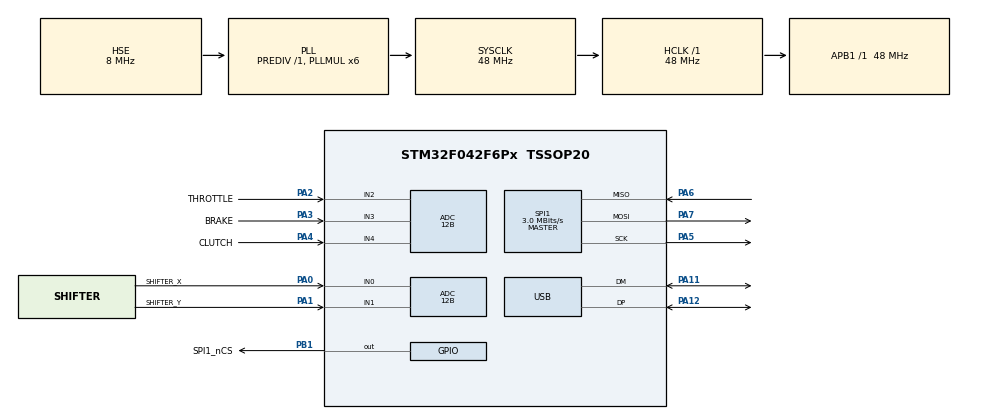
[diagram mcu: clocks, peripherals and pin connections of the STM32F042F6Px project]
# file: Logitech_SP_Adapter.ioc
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ADC.ClockPrescaler=ADC_CLOCK_ASYNC_DIV1
ADC.ContinuousConvMode=ENABLE
ADC.DMAContinuousRequests=ENABLE
ADC.DataAlign=ADC_DATAALIGN_RIGHT
ADC.DiscontinuousConvMode=DISABLE
ADC.EOCSelection=ADC_EOC_SEQ_CONV
ADC.EnableAnalogWatchDog=false
ADC.ExternalTrigConvEdge=ADC_EXTERNALTRIGCONVEDGE_NONE
ADC.LowPowerAutoPowerOff=DISABLE
ADC.LowPowerAutoWait=DISABLE
ADC.Overrun=ADC_OVR_DATA_OVERWRITTEN
ADC.Resolution=ADC_RESOLUTION_12B
ADC.SamplingTime=ADC_SAMPLETIME_7CYCLES_5
ADC.ScanConvMode=ADC_SCAN_DIRECTION_FORWARD
Dma.ADC.0.Direction=DMA_PERIPH_TO_MEMORY
Dma.ADC.0.Instance=DMA1_Channel1
Dma.ADC.0.MemDataAlignment=DMA_MDATAALIGN_WORD
Dma.ADC.0.MemInc=DMA_MINC_ENABLE
Dma.ADC.0.Mode=DMA_CIRCULAR
Dma.ADC.0.PeriphDataAlignment=DMA_PDATAALIGN_WORD
Dma.ADC.0.PeriphInc=DMA_PINC_DISABLE
Dma.ADC.0.Priority=DMA_PRIORITY_HIGH
Dma.Request0=ADC
Mcu.Family=STM32F0
Mcu.Name=STM32F042F6Px
Mcu.Package=TSSOP20
NVIC.DMA1_Channel1_IRQn=true\:0\:0\:false\:false\:true
NVIC.TIM14_IRQn=true\:0\:0\:false\:false\:true
NVIC.USB_IRQn=true\:0\:0\:false\:false\:true
PA0.GPIO_Label=SHIFTER_X
PA0.Mode=IN0
PA0.Signal=ADC_IN0
PA1.GPIO_Label=SHIFTER_Y
PA1.Mode=IN1
PA1.Signal=ADC_IN1
PA11.Mode=Device
PA11.Signal=USB_DM
PA12.Mode=Device
PA12.Signal=USB_DP
PA13.Mode=Serial_Wire
PA13.Signal=SYS_SWDIO
PA14.Mode=Serial_Wire
PA14.Signal=SYS_SWCLK
PA2.GPIO_Label=THROTTLE
PA2.Mode=IN2
PA2.Signal=ADC_IN2
PA3.GPIO_Label=BRAKE
PA3.Mode=IN3
PA3.Signal=ADC_IN3
PA4.GPIO_Label=CLUTCH
PA4.Mode=IN4
PA4.Signal=ADC_IN4
PA5.Mode=Full_Duplex_Master
PA5.Signal=SPI1_SCK
PA6.Mode=Full_Duplex_Master
PA6.Signal=SPI1_MISO
PA7.Mode=Full_Duplex_Master
PA7.Signal=SPI1_MOSI
PB1.GPIO_Label=SPI1_nCS
PB1.GPIO_Speed=GPIO_SPEED_FREQ_HIGH
PB1.Signal=GPIO_Output
PF0-OSC_IN.Mode=HSE-External-Oscillator
PF0-OSC_IN.Signal=RCC_OSC_IN
PF1-OSC_OUT.Mode=HSE-External-Oscillator
PF1-OSC_OUT.Signal=RCC_OSC_OUT
ProjectManager.HeapSize=0x200
ProjectManager.StackSize=0x400
ProjectManager.TargetToolchain=TrueSTUDIO
RCC.AHBFreq_Value=48000000
RCC.APB1Freq_Value=48000000
RCC.APB1TimFreq_Value=48000000
RCC.HCLKFreq_Value=48000000
RCC.HSIState=RCC_HSI_ON
RCC.PLLMUL=RCC_PLL_MUL6
RCC.SYSCLKFreq_VALUE=48000000
RCC.SYSCLKSource=RCC_SYSCLKSOURCE_PLLCLK
RCC.USBClockSelection=RCC_USBCLKSOURCE_PLL
RCC.USBFreq_Value=48000000
SPI1.BaudRatePrescaler=SPI_BAUDRATEPRESCALER_16
SPI1.CalculateBaudRate=3.0 MBits/s
SPI1.DataSize=SPI_DATASIZE_8BIT
SPI1.Mode=SPI_MODE_MASTER
TIM14.Period=10
TIM14.Prescaler=48
USB_DEVICE.MANUFACTURER_STRING=InterBiometrics
USB_DEVICE.PID_HID_FS=61453
USB_DEVICE.PRODUCT_STRING_HID_FS=Shifter/Pedals Adapter
USB_DEVICE.USBD_HandleTypeDef=hUsbDeviceFS
USB_DEVICE.VID=4617
USB_DEVICE.VirtualMode=Hid
USB_DEVICE.VirtualModeFS=Hid_FS
VP_SYS_VS_PINREMAP.Mode=PINREMAP
VP_TIM14_VS_ClockSourceINT.Mode=Enable_Timer
VP_USB_DEVICE_VS_USB_DEVICE_HID_FS.Mode=HID_FS
board=Logitech_SP_Adapter

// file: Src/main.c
/**
  ******************************************************************************
  * File Name          : main.c
  * Description        : Main program body
  ******************************************************************************
  *
  * COPYRIGHT(c) 2016 STMicroelectronics
  *
  * Redistribution and use in source and binary forms, with or without modification,
  * are permitted provided that the following conditions are met:
  *   1. Redistributions of source code must retain the above copyright notice,
  *      this list of conditions and the following disclaimer.
  *   2. Redistributions in binary form must reproduce the above copyright notice,
  *      this list of conditions and the following disclaimer in the documentation
  *      and/or other materials provided with the distribution.
  *   3. Neither the name of STMicroelectronics nor the names of its contributors
  *      may be used to endorse or promote products derived from this software
  *      without specific prior written permission.
  *
  * THIS SOFTWARE IS PROVIDED BY THE COPYRIGHT HOLDERS AND CONTRIBUTORS "AS IS"
  * AND ANY EXPRESS OR IMPLIED WARRANTIES, INCLUDING, BUT NOT LIMITED TO, THE
  * IMPLIED WARRANTIES OF MERCHANTABILITY AND FITNESS FOR A PARTICULAR PURPOSE ARE
  * DISCLAIMED. IN NO EVENT SHALL THE COPYRIGHT HOLDER OR CONTRIBUTORS BE LIABLE
  * FOR ANY DIRECT, INDIRECT, INCIDENTAL, SPECIAL, EXEMPLARY, OR CONSEQUENTIAL
  * DAMAGES (INCLUDING, BUT NOT LIMITED TO, PROCUREMENT OF SUBSTITUTE GOODS OR
  * SERVICES; LOSS OF USE, DATA, OR PROFITS; OR BUSINESS INTERRUPTION) HOWEVER
  * CAUSED AND ON ANY THEORY OF LIABILITY, WHETHER IN CONTRACT, STRICT LIABILITY,
  * OR TORT (INCLUDING NEGLIGENCE OR OTHERWISE) ARISING IN ANY WAY OUT OF THE USE
  * OF THIS SOFTWARE, EVEN IF ADVISED OF THE POSSIBILITY OF SUCH DAMAGE.
  *
  ******************************************************************************
  */
#include "stm32f0xx_hal.h"
#include "usb_device.h"

/* USER CODE BEGIN Includes */
#include "usbd_hid.h"
#include "eeprom.h"
/* USER CODE END Includes */

TIM_HandleTypeDef htim14;

ADC_HandleTypeDef hadc;
DMA_HandleTypeDef hdma_adc;
SPI_HandleTypeDef hspi1;

#define X_AXIS_LOW_TH	1400
#define X_AXIS_HIGH_TH	2500
#define Y_AXIS_LOW_TH	500
#define Y_AXIS_HIGH_TH	2600

#define X_AXIS			(axis[0] & 0xffffu)
#define Y_AXIS			(axis[1] & 0xffffu)
#define T_AXIS			(axis[2] & 0xffffu)
#define B_AXIS			(axis[3] & 0xffffu)
#define C_AXIS			(axis[4] & 0xffffu)

__ALIGN_BEGIN static volatile uint32_t axis[5] __ALIGN_END = { 0, 0, 0, 0, 0 };    // Y, X, T, B, C
__ALIGN_BEGIN static uint8_t rx_buffer[2] __ALIGN_END;

/* Virtual address defined by the user: 0xFFFF value is prohibited */
#define X_AXIS_LOW_VADDR	0x1001
#define X_AXIS_HIGH_VADDR	0x1002
#define Y_AXIS_LOW_VADDR	0x1003
#define Y_AXIS_HIGH_VADDR	0x1004

__ALIGN_BEGIN uint16_t VirtAddVarTab[NB_OF_VAR] __ALIGN_END =
{
    X_AXIS_LOW_VADDR, X_AXIS_HIGH_VADDR, Y_AXIS_LOW_VADDR, Y_AXIS_HIGH_VADDR
};

struct __packed
{
    uint8_t		id;			// 0x01
    uint8_t		buttons[3];
    uint16_t	axis[5];
} report = { 1, { 0, 0, 0 }, { 0, 0, 0, 0, 0 } };

unsigned short x_low_th  = X_AXIS_LOW_TH;
unsigned short y_low_th  = Y_AXIS_LOW_TH;
unsigned short x_high_th = X_AXIS_HIGH_TH;
unsigned short y_high_th = Y_AXIS_HIGH_TH;

unsigned short report2send = 0;
static unsigned short x_axis = 2048;
static unsigned short y_axis = 2048;

static volatile uint32_t u100ticks = 0;

void SystemClock_Config(void);
void Error_Handler(void);
static void MX_GPIO_Init(void);
static void MX_DMA_Init(void);
static void MX_ADC_Init(void);
static void MX_SPI1_Init(void);
static void MX_TIM14_Init(void);

void HAL_ADC_ConvCpltCallback(ADC_HandleTypeDef * hadc);

int main(void)
{
    /* Reset of all peripherals, Initializes the Flash interface and the Systick. */
    HAL_Init();

    /* Configure the system clock */
    SystemClock_Config();

    /* Initialize all configured peripherals */
    MX_GPIO_Init();
    MX_DMA_Init();
    MX_ADC_Init();
    MX_SPI1_Init();
    MX_USB_DEVICE_Init();
    MX_TIM14_Init();

    HAL_FLASH_Unlock();
    EE_Init();

    EE_ReadVariable(VirtAddVarTab[0], &x_low_th);
    EE_ReadVariable(VirtAddVarTab[1], &x_high_th);
    EE_ReadVariable(VirtAddVarTab[2], &y_low_th);
    EE_ReadVariable(VirtAddVarTab[3], &y_high_th);

    HAL_FLASH_Lock();

    HAL_ADC_Start_DMA(&hadc, (uint32_t*)axis, 5);

    while (1)
    {
        HAL_GPIO_WritePin(SPI1_nCS_GPIO_Port, SPI1_nCS_Pin, GPIO_PIN_SET);

        HAL_TIM_Base_Start_IT(&htim14);
        while (!u100ticks) /* do nothing for 100 us */;
        HAL_TIM_Base_Stop_IT(&htim14);
        u100ticks = 0;

        HAL_StatusTypeDef status =
            HAL_SPI_Receive(&hspi1, rx_buffer, sizeof(rx_buffer), 3000);

        switch(status)
        {
        case HAL_OK:
            report.buttons[0] = 0x00;
            // report.buttons[1] = 0x00;
            report.buttons[2] = 0x00;

            if ((rx_buffer[0] & 0xff) != 0xff)   // if all bits of rx_buffer[0] is 1 assume shifter is disconnected
            {
                if (rx_buffer[0] & 4)   report.buttons[0] |= 1;         else report.buttons[0] &= ~1;
                if (rx_buffer[0] & 1)   report.buttons[0] |= (1 << 1);  else report.buttons[0] &= ~(1 << 1);
                if (rx_buffer[0] & 2)   report.buttons[0] |= (1 << 2);  else report.buttons[0] &= ~(1 << 2);
                if (rx_buffer[0] & 8)   report.buttons[0] |= (1 << 3);  else report.buttons[0] &= ~(1 << 3);

                if (rx_buffer[1] & 1)   report.buttons[2] |= 1;         else report.buttons[2] &= ~1;
                if (rx_buffer[1] & 2)   report.buttons[2] |= (1 << 1);  else report.buttons[2] &= ~(1 << 1);
                if (rx_buffer[1] & 4)   report.buttons[2] |= (1 << 2);  else report.buttons[2] &= ~(1 << 2);
                if (rx_buffer[1] & 8)   report.buttons[2] |= (1 << 3);  else report.buttons[2] &= ~(1 << 3);

                if (rx_buffer[1] & 32)  report.buttons[0] |= (1 << 4);  else report.buttons[0] &= ~(1 << 4);
                if (rx_buffer[1] & 128) report.buttons[0] |= (1 << 5);  else report.buttons[0] &= ~(1 << 5);
                if (rx_buffer[1] & 64)  report.buttons[0] |= (1 << 6);  else report.buttons[0] &= ~(1 << 6);
                if (rx_buffer[1] & 16)  report.buttons[0] |= (1 << 7);  else report.buttons[0] &= ~(1 << 7);
            }
            break;

        case HAL_TIMEOUT:
        case HAL_BUSY:
        case HAL_ERROR:
            Error_Handler();
        default:
            report.buttons[0] = 0xff;
            break;
        }

        HAL_GPIO_WritePin(SPI1_nCS_GPIO_Port, SPI1_nCS_Pin, GPIO_PIN_RESET);
        report.id = 0x01;

        x_axis = ((X_AXIS << 2) + x_axis * 96) / 100;
        y_axis = ((Y_AXIS << 2) + y_axis * 96) / 100;

        if (rx_buffer[0] & 16)
        {
            if (y_axis < y_low_th)   // stick towards player
            {
                report.buttons[1] = 128;
                report.buttons[2] &= ~(1 << 4);
            }
            else if (y_axis > y_high_th)   // stick opposite to player
            {
                report.buttons[1] = 0; // neutral
                report.buttons[2] |= (1 << 4);
            }
            else
            {
                report.buttons[1] = 0; // neutral
                report.buttons[2] &= ~(1 << 4);
            }
        }
        else
        {
            report.buttons[1] &= ~(1 << 7);
            report.buttons[2] &= ~(1 << 4);

            if (y_axis < y_low_th)   // stick towards player
            {
                if (x_axis < x_low_th)
                {
                    if (!report.buttons[1]) report.buttons[1] = 2; // 2nd gear
                }
                else if (!report.buttons[1])
                {
                    report.buttons[1] = (x_axis > x_high_th) ? ((rx_buffer[0] & 64) ? 64 : 32) : 8;
                }
            }
            else
            {
                if (y_axis > y_high_th)   // stick opposite to player
                {
                    if (x_axis < x_low_th)
                    {
                        if (!report.buttons[1]) report.buttons[1] = 1; // 1st gear
                    }
                    else if (!report.buttons[1])
                    {
                        report.buttons[1] = (x_axis > x_high_th) ? 16 : 4;
                    }
                }
                else
                {
                    report.buttons[1] = 0; // neutral
                }
            }
        }

        report.axis[0] = x_axis;
        report.axis[1] = y_axis;

        if (report2send == 2)
        {
            HAL_FLASH_Unlock();

            EE_WriteVariable(VirtAddVarTab[0], x_low_th);
            EE_WriteVariable(VirtAddVarTab[1], x_high_th);
            EE_WriteVariable(VirtAddVarTab[2], y_low_th);
            EE_WriteVariable(VirtAddVarTab[3], y_high_th);

            HAL_FLASH_Lock();
            report2send = 0;
        }

        if (hUsbDeviceFS.pClassData
                && ((USBD_HID_HandleTypeDef *)hUsbDeviceFS.pClassData)->state == HID_IDLE)
        {
            USBD_HID_SendReport(&hUsbDeviceFS, (uint8_t *)&report, sizeof(report));
        }
    }
}

/** System Clock Configuration
*/
void SystemClock_Config(void)
{

    RCC_OscInitTypeDef RCC_OscInitStruct;
    RCC_ClkInitTypeDef RCC_ClkInitStruct;
    RCC_PeriphCLKInitTypeDef PeriphClkInit;

    RCC_OscInitStruct.OscillatorType = RCC_OSCILLATORTYPE_HSI14|RCC_OSCILLATORTYPE_HSE;
    RCC_OscInitStruct.HSEState = RCC_HSE_ON;
//  RCC_OscInitStruct.OscillatorType = RCC_OSCILLATORTYPE_HSI14|RCC_OSCILLATORTYPE_HSI48;
//  RCC_OscInitStruct.HSI48State = RCC_HSI48_ON;

    RCC_OscInitStruct.HSI14State = RCC_HSI14_ON;
    RCC_OscInitStruct.HSI14CalibrationValue = RCC_HSI14CALIBRATION_DEFAULT;

    RCC_OscInitStruct.PLL.PLLState = RCC_PLL_ON;
//  RCC_OscInitStruct.PLL.PLLState = RCC_PLL_NONE;
    RCC_OscInitStruct.PLL.PLLSource = RCC_PLLSOURCE_HSE;
    RCC_OscInitStruct.PLL.PLLMUL = RCC_PLL_MUL6;
    RCC_OscInitStruct.PLL.PREDIV = RCC_PREDIV_DIV1;

    if (HAL_RCC_OscConfig(&RCC_OscInitStruct) != HAL_OK)
    {
        Error_Handler();
    }

    RCC_ClkInitStruct.ClockType = RCC_CLOCKTYPE_HCLK|RCC_CLOCKTYPE_SYSCLK
                                  |RCC_CLOCKTYPE_PCLK1;
    RCC_ClkInitStruct.SYSCLKSource = RCC_SYSCLKSOURCE_PLLCLK;
//  RCC_ClkInitStruct.SYSCLKSource = RCC_SYSCLKSOURCE_HSI48;

    RCC_ClkInitStruct.AHBCLKDivider = RCC_SYSCLK_DIV1;
    RCC_ClkInitStruct.APB1CLKDivider = RCC_HCLK_DIV1;
    if (HAL_RCC_ClockConfig(&RCC_ClkInitStruct, FLASH_LATENCY_1) != HAL_OK)
    {
        Error_Handler();
    }

    PeriphClkInit.PeriphClockSelection = RCC_PERIPHCLK_USB;
    PeriphClkInit.UsbClockSelection = RCC_USBCLKSOURCE_PLL;
//  PeriphClkInit.UsbClockSelection = RCC_USBCLKSOURCE_HSI48;

    if (HAL_RCCEx_PeriphCLKConfig(&PeriphClkInit) != HAL_OK)
    {
        Error_Handler();
    }

    HAL_SYSTICK_Config(HAL_RCC_GetHCLKFreq()/1000);

    HAL_SYSTICK_CLKSourceConfig(SYSTICK_CLKSOURCE_HCLK);

    /* SysTick_IRQn interrupt configuration */
    HAL_NVIC_SetPriority(SysTick_IRQn, 0, 0);
}

/* TIM14 init function */
static void MX_TIM14_Init(void)
{

    htim14.Instance = TIM14;
    htim14.Init.Prescaler = 48;
    htim14.Init.CounterMode = TIM_COUNTERMODE_UP;
    htim14.Init.Period = 100; /* generate IRQ 48 MHz / 48 / 100 = 10,000 times per second */
    htim14.Init.ClockDivision = TIM_CLOCKDIVISION_DIV1;
    if (HAL_TIM_Base_Init(&htim14) != HAL_OK)
    {
        Error_Handler();
    }

}

/* ADC init function */
static void MX_ADC_Init(void)
{

    ADC_ChannelConfTypeDef sConfig;

    /**Configure the global features of the ADC (Clock, Resolution, Data Alignment and number of conversion)
    */
    hadc.Instance = ADC1;
    hadc.Init.ClockPrescaler = ADC_CLOCK_ASYNC_DIV1;
    hadc.Init.Resolution = ADC_RESOLUTION_12B;
    hadc.Init.DataAlign = ADC_DATAALIGN_RIGHT;
    hadc.Init.ScanConvMode = ADC_SCAN_DIRECTION_FORWARD;
    hadc.Init.EOCSelection = ADC_EOC_SEQ_CONV;
    hadc.Init.LowPowerAutoWait = DISABLE;
    hadc.Init.LowPowerAutoPowerOff = DISABLE;
    hadc.Init.ContinuousConvMode = ENABLE;
    hadc.Init.DiscontinuousConvMode = DISABLE;
    hadc.Init.ExternalTrigConv = ADC_SOFTWARE_START;
    hadc.Init.SamplingTimeCommon = ADC_SAMPLETIME_239CYCLES_5;
    hadc.Init.ExternalTrigConvEdge = ADC_EXTERNALTRIGCONVEDGE_NONE;
    hadc.Init.DMAContinuousRequests = ENABLE;
    hadc.Init.Overrun = ADC_OVR_DATA_OVERWRITTEN;
    if (HAL_ADC_Init(&hadc) != HAL_OK)
    {
        Error_Handler();
    }

    /**Configure for the selected ADC regular channel to be converted.
    */
    sConfig.Channel = ADC_CHANNEL_0;
    sConfig.Rank = ADC_RANK_CHANNEL_NUMBER;
    sConfig.SamplingTime = ADC_SAMPLETIME_239CYCLES_5;
    if (HAL_ADC_ConfigChannel(&hadc, &sConfig) != HAL_OK)
    {
        Error_Handler();
    }

    /**Configure for the selected ADC regular channel to be converted.
    */
    sConfig.Channel = ADC_CHANNEL_1;
    if (HAL_ADC_ConfigChannel(&hadc, &sConfig) != HAL_OK)
    {
        Error_Handler();
    }

    /**Configure for the selected ADC regular channel to be converted.
    */
    sConfig.Channel = ADC_CHANNEL_2;
    if (HAL_ADC_ConfigChannel(&hadc, &sConfig) != HAL_OK)
    {
        Error_Handler();
    }

    /**Configure for the selected ADC regular channel to be converted.
    */
    sConfig.Channel = ADC_CHANNEL_3;
    if (HAL_ADC_ConfigChannel(&hadc, &sConfig) != HAL_OK)
    {
        Error_Handler();
    }

    /**Configure for the selected ADC regular channel to be converted.
    */
    sConfig.Channel = ADC_CHANNEL_4;
    if (HAL_ADC_ConfigChannel(&hadc, &sConfig) != HAL_OK)
    {
        Error_Handler();
    }

}

// ADC DMA interrupt handler
void HAL_ADC_ConvCpltCallback(ADC_HandleTypeDef *hadc)
{

    report.axis[2] = ((T_AXIS << 1) + report.axis[2] * 98) / 100;
    report.axis[3] = ((B_AXIS << 1) + report.axis[3] * 98) / 100;
    report.axis[4] = ((C_AXIS << 1) + report.axis[4] * 98) / 100;
}

void HAL_TIM_PeriodElapsedCallback(TIM_HandleTypeDef *htim)
{
    if (htim->Instance == TIM14)
    {
        u100ticks++;
    }
}

/* SPI1 init function */
static void MX_SPI1_Init(void)
{

    hspi1.Instance = SPI1;
    hspi1.Init.Mode = SPI_MODE_MASTER;
    hspi1.Init.Direction = SPI_DIRECTION_2LINES;
    hspi1.Init.DataSize = SPI_DATASIZE_8BIT;
    hspi1.Init.CLKPolarity = SPI_POLARITY_LOW;
    hspi1.Init.CLKPhase = SPI_PHASE_1EDGE;
    hspi1.Init.NSS = SPI_NSS_SOFT;
    hspi1.Init.BaudRatePrescaler = SPI_BAUDRATEPRESCALER_16;
    hspi1.Init.FirstBit = SPI_FIRSTBIT_MSB;
    hspi1.Init.TIMode = SPI_TIMODE_DISABLE;
    hspi1.Init.CRCCalculation = SPI_CRCCALCULATION_DISABLE;
    hspi1.Init.CRCPolynomial = 7;
    hspi1.Init.CRCLength = SPI_CRC_LENGTH_DATASIZE;
    hspi1.Init.NSSPMode = SPI_NSS_PULSE_ENABLE;
    if (HAL_SPI_Init(&hspi1) != HAL_OK)
    {
        Error_Handler();
    }

}

static void MX_DMA_Init(void)
{
    /* DMA controller clock enable */
    __HAL_RCC_DMA1_CLK_ENABLE();

    /* DMA interrupt init */
    /* DMA1_Channel1_IRQn interrupt configuration */
    HAL_NVIC_SetPriority(DMA1_Channel1_IRQn, 0, 0);
    HAL_NVIC_EnableIRQ(DMA1_Channel1_IRQn);

}

/** Configure pins as
        * Analog
        * Input
        * Output
        * EVENT_OUT
        * EXTI
*/
static void MX_GPIO_Init(void)
{

    GPIO_InitTypeDef GPIO_InitStruct;

    /* GPIO Ports Clock Enable */
    __HAL_RCC_GPIOF_CLK_ENABLE();
    __HAL_RCC_GPIOA_CLK_ENABLE();
    __HAL_RCC_GPIOB_CLK_ENABLE();

    /*Configure GPIO pin Output Level */
    HAL_GPIO_WritePin(SPI1_nCS_GPIO_Port, SPI1_nCS_Pin, GPIO_PIN_RESET);

    /*Configure GPIO pin : SPI1_nCS_Pin */
    GPIO_InitStruct.Pin = SPI1_nCS_Pin;
    GPIO_InitStruct.Mode = GPIO_MODE_OUTPUT_PP;
    GPIO_InitStruct.Pull = GPIO_NOPULL;
    GPIO_InitStruct.Speed = GPIO_SPEED_FREQ_HIGH;
    HAL_GPIO_Init(SPI1_nCS_GPIO_Port, &GPIO_InitStruct);

}

void Error_Handler(void)
{
    while(1)
    {
    }
}

/************************ (C) COPYRIGHT STMicroelectronics *****END OF FILE****/
